# IWRL6432 register map
File version: 1.0
CPU: CM4 1.0, other endian, MPU, FPU, 3 interrupt priority bits
Registers are 32-bit, read-write, reset 0x0 unless marked. A register's access mark holds for its fields unless they carry their own. Offsets are from the block's base; [hi:lo] are bit positions.

## TOP_GIO
Base 0x5AF7FC00
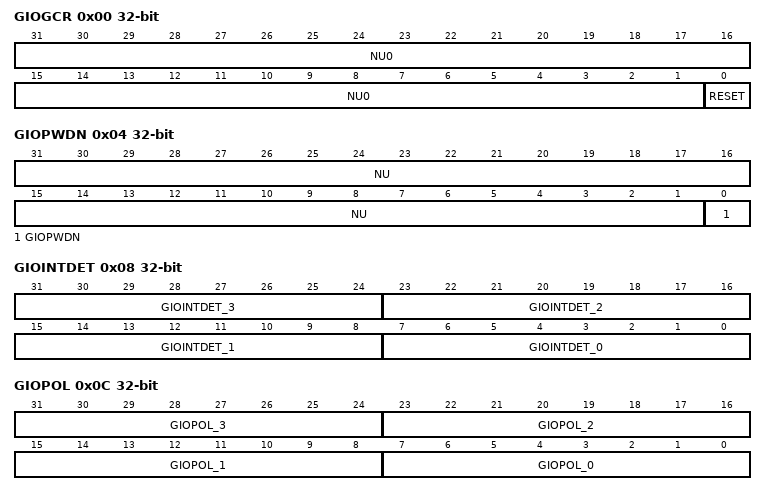
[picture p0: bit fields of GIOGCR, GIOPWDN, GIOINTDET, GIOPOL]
0x00 GIOGCR — GIO reset
  [31:1] NU0 — [31:1] Reserved
  [0] RESET — [0:0] GIO reset
0x04 GIOPWDN — GIO power down mode register
  [31:1] NU — [31:1] Reserved
  [0] GIOPWDN — [0:0] Writing to the GIOPWDN bit is only allowed in privilege mode. Reading of the GIOPWDN bit is allowed in all modes. Privilege mode (write): 0 = Normal operation; clocks enabled to GIO module 1 = Power-down mode User mode (write): Writes have no effect in user mode. User or privilege mode (read): 0 = Normal operation; clocks enabled to GIO module 1 = Power-down mode
0x08 GIOINTDET — Interrupt detection select for pins [0:1] GIO[7:0].
  [31:24] GIOINTDET_3 — [31:24] Interrupt detection select for pins GIOD[7:0].
  [23:16] GIOINTDET_2 — [23:16] Interrupt detection select for pins GIOC[7:0].
  [15:8] GIOINTDET_1 — [15:8] Interrupt detection select for pins GIOB[7:0].
  [7:0] GIOINTDET_0 — [7:0] Interrupt detection select for pins GIOA[7:0].
0x0C GIOPOL — Interrupt polarity select for pins [0:1] GIO[7:0].
  [31:24] GIOPOL_3 — [31:24] Interrupt polarity select for pins GIOD[7:0]
  [23:16] GIOPOL_2 — [23:16] Interrupt polarity select for pins GIOC[7:0]
  [15:8] GIOPOL_1 — [15:8] Interrupt polarity select for pins GIOB[7:0]
  [7:0] GIOPOL_0 — [7:0] Interrupt polarity select for pins GIOA[7:0]
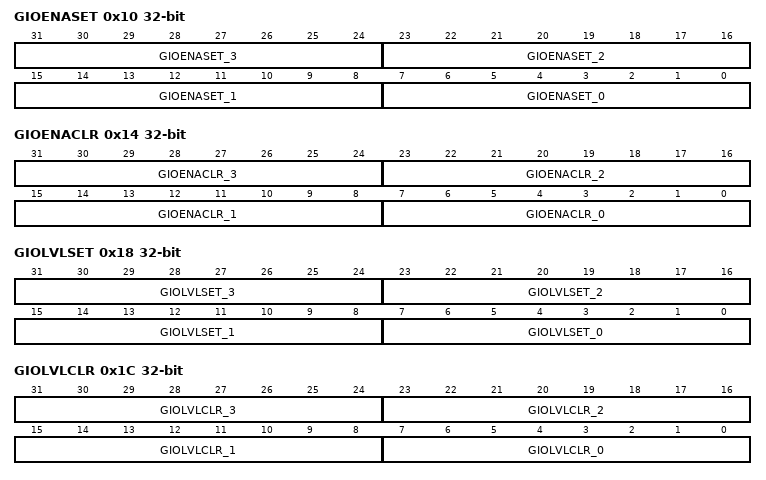
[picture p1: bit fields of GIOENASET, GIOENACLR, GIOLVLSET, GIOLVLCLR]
0x10 GIOENASET — Interrupt enable for pins [0:1] GIO[7:0].
  [31:24] GIOENASET_3 — [31:24] Interrupt enable for pins GIOD [7:0]
  [23:16] GIOENASET_2 — [23:16] Interrupt enable for pins GIOC [7:0]
  [15:8] GIOENASET_1 — [15:8] Interrupt enable for pins GIOB [7:0]
  [7:0] GIOENASET_0 — [7:0] Interrupt enable for pins GIOA [7:0]
0x14 GIOENACLR — Interrupt enable for pins [0:1] GIO[7:0].
  [31:24] GIOENACLR_3 — [31:24] Interrupt enable for pins GIOD [7:0]
  [23:16] GIOENACLR_2 — [23:16] Interrupt enable for pins GIOC [7:0]
  [15:8] GIOENACLR_1 — [15:8] Interrupt enable for pins GIOB [7:0]
  [7:0] GIOENACLR_0 — [7:0] Interrupt enable for pins GIOA [7:0]
0x18 GIOLVLSET — GIO high priority interrupt for pins [0:1] GIO[7:0].
  [31:24] GIOLVLSET_3 — [31:24] GIO high priority interrupt for pins GIOD[7:0]
  [23:16] GIOLVLSET_2 — [23:16] GIO high priority interrupt for pins GIOC[7:0]
  [15:8] GIOLVLSET_1 — [15:8] GIO high priority interrupt for pins GIOB[7:0]
  [7:0] GIOLVLSET_0 — [7:0] GIO high priority interrupt for pins GIOA[7:0]
0x1C GIOLVLCLR — GIO low priority interrupt for pins [0:1] GIO[7:0].
  [31:24] GIOLVLCLR_3 — [31:24] GIO low priority interrupt for pins GIOD[7:0]
  [23:16] GIOLVLCLR_2 — [23:16] GIO low priority interrupt for pins GIOC[7:0]
  [15:8] GIOLVLCLR_1 — [15:8] GIO low priority interrupt for pins GIOB[7:0]
  [7:0] GIOLVLCLR_0 — [7:0] GIO low priority interrupt for pins GIOA[7:0]
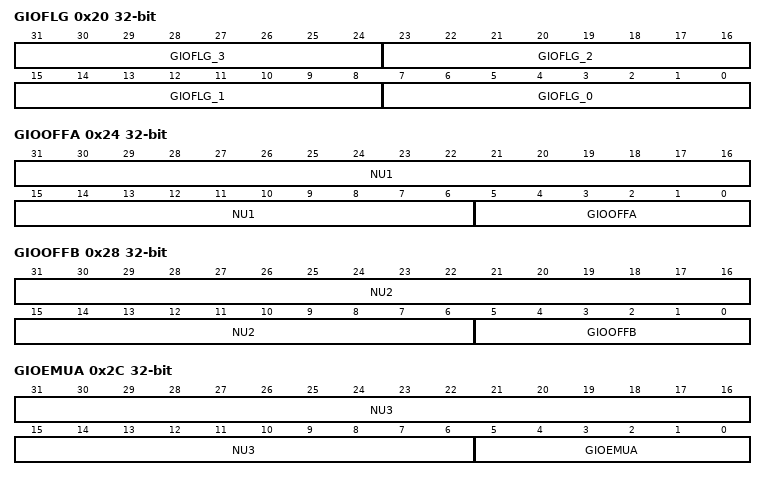
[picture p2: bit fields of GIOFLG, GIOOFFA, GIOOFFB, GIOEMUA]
0x20 GIOFLG — GIO flag for pins [0:1] GIO[7:0].
  [31:24] GIOFLG_3 — [31:24] GIO flag for pins GIOD[7:0]
  [23:16] GIOFLG_2 — [23:16] GIO flag for pins GIOC[7:0]
  [15:8] GIOFLG_1 — [15:8] GIO flag for pins GIOB[7:0]
  [7:0] GIOFLG_0 — [7:0] GIO flag for pins GIOA[7:0]
0x24 GIOOFFA — Index bits for currently pending high-priority interrupt Register A
  [31:6] NU1 — [31:6] Reserved
  [5:0] GIOOFFA — [5:0] Index bits for currently pending high-priority interrupt Register A
0x28 GIOOFFB — Index bits for currently pending high-priority interrupt Register B
  [31:6] NU2 — [31:6] Reserved
  [5:0] GIOOFFB — [5:0] Index bits for currently pending high-priority interrupt Register B
0x2C GIOEMUA — GIO emulation register A
  [31:6] NU3 — [31:6] Reserved
  [5:0] GIOEMUA — [5:0] GIO emulation register A
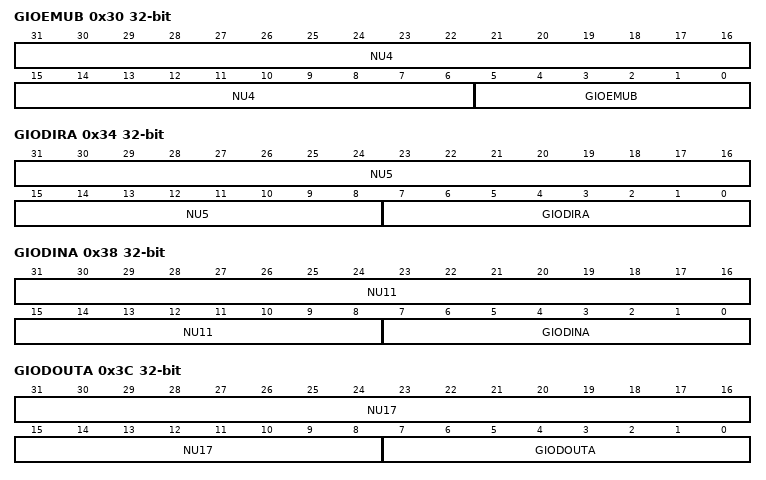
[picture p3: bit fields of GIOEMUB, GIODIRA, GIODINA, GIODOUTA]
0x30 GIOEMUB — GIO emulation register B
  [31:6] NU4 — [31:6] Reserved
  [5:0] GIOEMUB — [5:0] GIO emulation register B
0x34 GIODIRA — GIO data direction of pins in Port A
  [31:8] NU5 — [31:8] Reserved
  [7:0] GIODIRA — [7:0] GIO data direction of pins in Port A
0x38 GIODINA — GIO data input for pins in port A
  [31:8] NU11 — [31:8] Reserved
  [7:0] GIODINA — [7:0] GIO data input for pins in port A
0x3C GIODOUTA — GIO data output for pins in port A
  [31:8] NU17 — [31:8] Reserved
  [7:0] GIODOUTA — [7:0] GIO data output for pins in port A
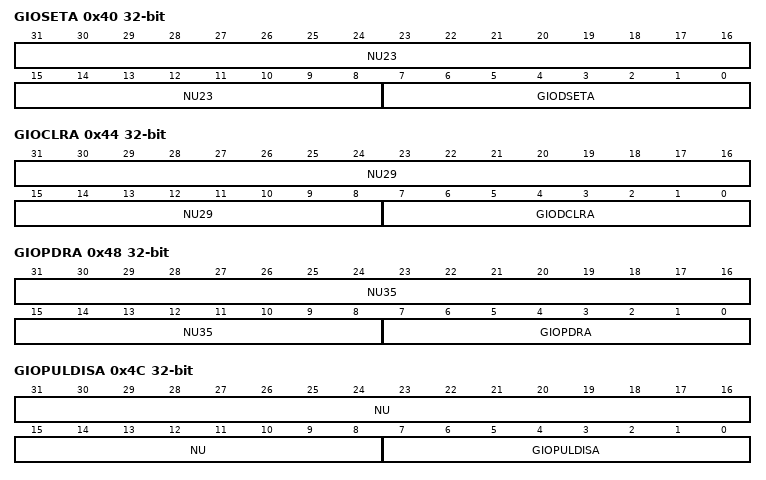
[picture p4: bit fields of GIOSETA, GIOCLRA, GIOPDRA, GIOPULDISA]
0x40 GIOSETA — GIO data set for port A
  [31:8] NU23 — [31:8] Reserved
  [7:0] GIODSETA — [7:0] GIO data set for port A
0x44 GIOCLRA — GIO data clear for port A
  [31:8] NU29 — [31:8] Reserved
  [7:0] GIODCLRA — [7:0] GIO data clear for port A
0x48 GIOPDRA — GIO open drain for port A
  [31:8] NU35 — [31:8] Reserved
  [7:0] GIOPDRA — [7:0] GIO open drain for port A
0x4C GIOPULDISA — GIO pul disable for port A
  [31:8] NU — [31:8] Reserved
  [7:0] GIOPULDISA — [7:0] GIO pull disable for port A
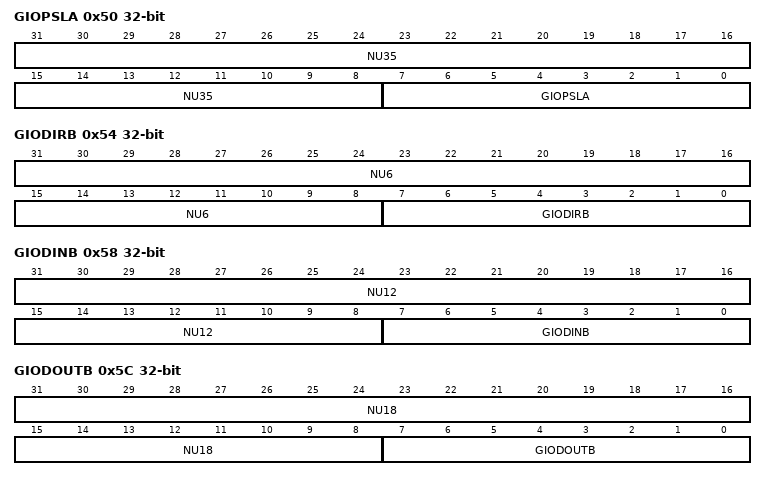
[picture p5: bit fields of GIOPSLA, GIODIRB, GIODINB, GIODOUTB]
0x50 GIOPSLA — GIO pul select for port A
  [31:8] NU35 — [31:8] Reserved
  [7:0] GIOPSLA — [7:0] GIO pull select for port A
0x54 GIODIRB — GIO data direction of pins in Port B
  [31:8] NU6 — [31:8] Reserved
  [7:0] GIODIRB — [7:0] GIO data direction of pins in Port B
0x58 GIODINB — GIO data input for pins in port B
  [31:8] NU12 — [31:8] Reserved
  [7:0] GIODINB — [7:0] GIO data input for pins in port B
0x5C GIODOUTB — GIO data output for pins in port B
  [31:8] NU18 — [31:8] Reserved
  [7:0] GIODOUTB — [7:0] GIO data output for pins in port B
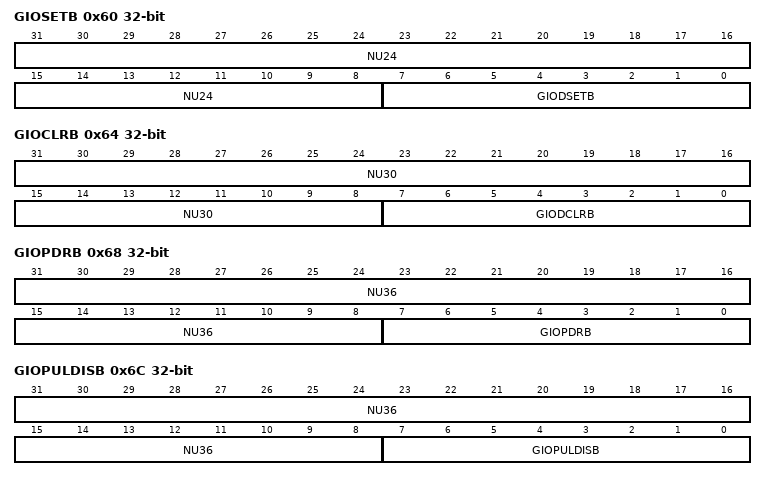
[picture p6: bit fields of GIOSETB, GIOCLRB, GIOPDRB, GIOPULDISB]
0x60 GIOSETB — GIO data set for port B
  [31:8] NU24 — [31:8] Reserved
  [7:0] GIODSETB — [7:0] GIO data set for port B
0x64 GIOCLRB — GIO data clear for port B
  [31:8] NU30 — [31:8] Reserved
  [7:0] GIODCLRB — [7:0] GIO data clear for port B
0x68 GIOPDRB — GIO open drain for port B
  [31:8] NU36 — [31:8] Reserved
  [7:0] GIOPDRB — [7:0] GIO open drain for port B
0x6C GIOPULDISB — GIO pul disable for port B
  [31:8] NU36 — [31:8] Reserved
  [7:0] GIOPULDISB — [7:0] GIO pull disable for port B
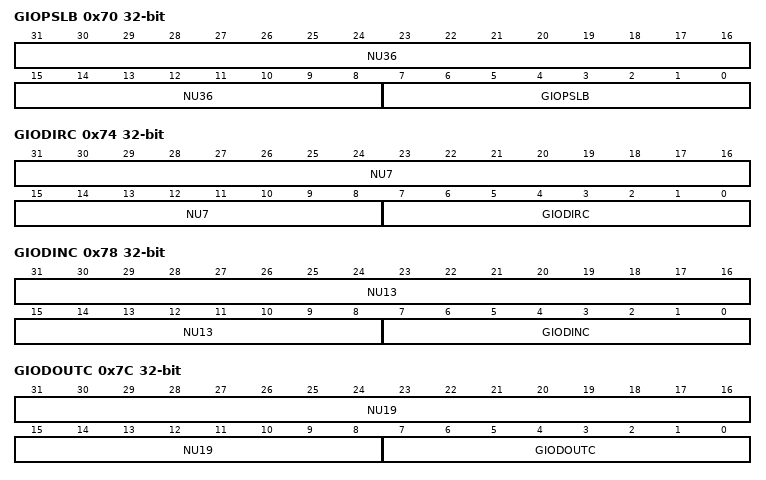
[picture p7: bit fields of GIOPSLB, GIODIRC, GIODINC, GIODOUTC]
0x70 GIOPSLB — GIO pul select for port B
  [31:8] NU36 — [31:8] Reserved
  [7:0] GIOPSLB — [7:0] GIO pull select for port B
0x74 GIODIRC — GIO data direction of pins in Port C
  [31:8] NU7 — [31:8] Reserved
  [7:0] GIODIRC — [7:0] GIO data direction of pins in Port C
0x78 GIODINC — GIO data input for pins in port C
  [31:8] NU13 — [31:8] Reserved
  [7:0] GIODINC — [7:0] GIO data input for pins in port C
0x7C GIODOUTC — GIO data output for pins in port C
  [31:8] NU19 — [31:8] Reserved
  [7:0] GIODOUTC — [7:0] GIO data output for pins in port C
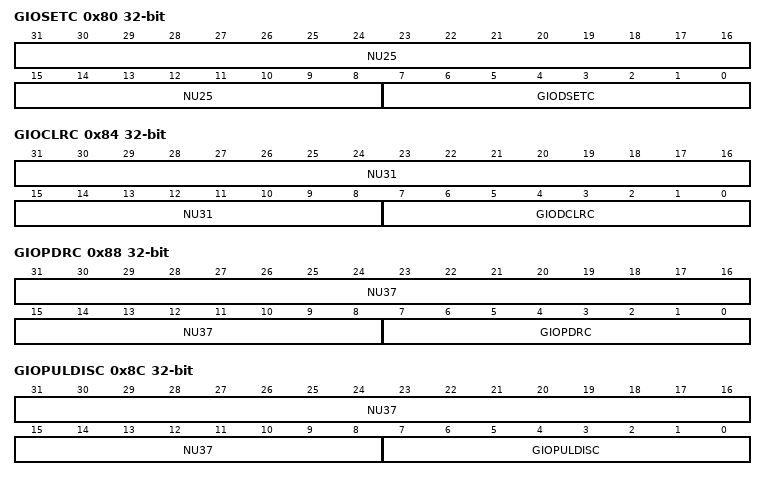
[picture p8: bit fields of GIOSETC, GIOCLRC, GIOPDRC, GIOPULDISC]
0x80 GIOSETC — GIO data set for port C
  [31:8] NU25 — [31:8] Reserved
  [7:0] GIODSETC — [7:0] GIO data set for port C
0x84 GIOCLRC — GIO data clear for port C
  [31:8] NU31 — [31:8] Reserved
  [7:0] GIODCLRC — [7:0] GIO data clear for port C
0x88 GIOPDRC — GIO open drain for port C
  [31:8] NU37 — [31:8] Reserved
  [7:0] GIOPDRC — [7:0] GIO open drain for port C
0x8C GIOPULDISC — GIO pul disable for port C
  [31:8] NU37 — [31:8] Reserved
  [7:0] GIOPULDISC — [7:0] GIO pull disable for port C
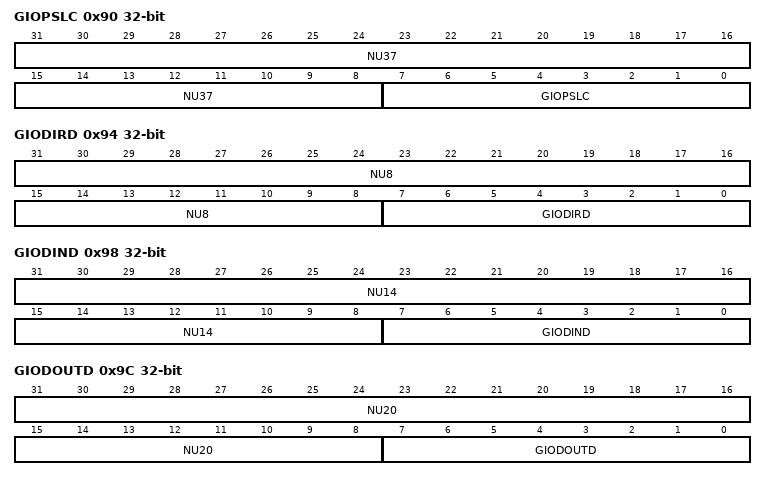
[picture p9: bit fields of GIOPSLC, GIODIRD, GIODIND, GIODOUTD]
0x90 GIOPSLC — GIO pul select for port C
  [31:8] NU37 — [31:8] Reserved
  [7:0] GIOPSLC — [7:0] GIO pull select for port C
0x94 GIODIRD — GIO data direction of pins in Port D
  [31:8] NU8 — [31:8] Reserved
  [7:0] GIODIRD — [7:0] GIO data direction of pins in Port D
0x98 GIODIND — GIO data input for pins in port D
  [31:8] NU14 — [31:8] Reserved
  [7:0] GIODIND — [7:0] GIO data input for pins in port D
0x9C GIODOUTD — GIO data output for pins in port D
  [31:8] NU20 — [31:8] Reserved
  [7:0] GIODOUTD — [7:0] GIO data output for pins in port D
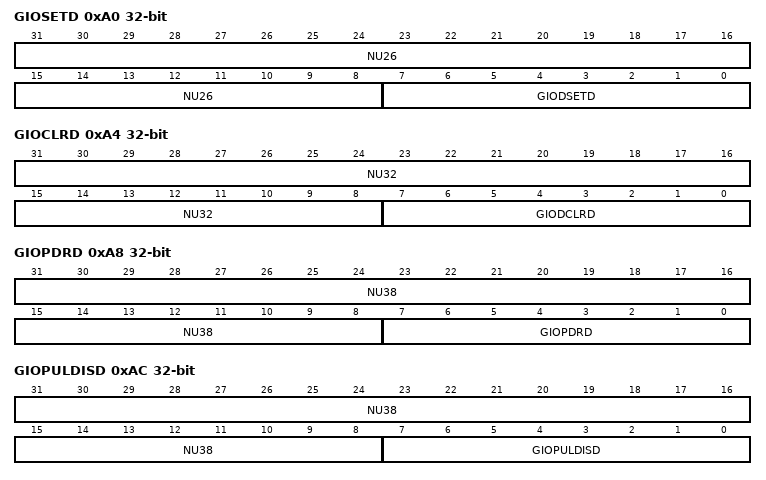
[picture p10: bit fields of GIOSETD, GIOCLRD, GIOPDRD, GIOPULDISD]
0xA0 GIOSETD — GIO data set for port D
  [31:8] NU26 — [31:8] Reserved
  [7:0] GIODSETD — [7:0] GIO data set for port D
0xA4 GIOCLRD — GIO data clear for port D
  [31:8] NU32 — [31:8] Reserved
  [7:0] GIODCLRD — [7:0] GIO data clear for port D
0xA8 GIOPDRD — GIO open drain for port D
  [31:8] NU38 — [31:8] Reserved
  [7:0] GIOPDRD — [7:0] GIO open drain for port D
0xAC GIOPULDISD — GIO pul disable for port D
  [31:8] NU38 — [31:8] Reserved
  [7:0] GIOPULDISD — [7:0] GIO pull disable for port D
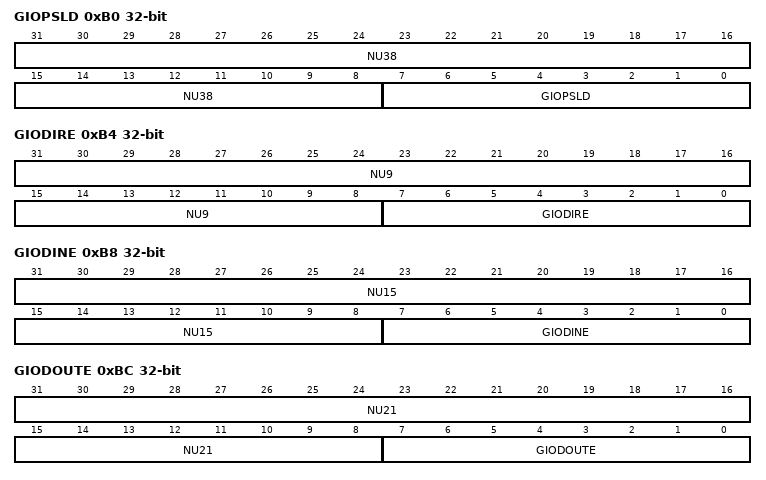
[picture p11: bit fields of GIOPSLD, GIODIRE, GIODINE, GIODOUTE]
0xB0 GIOPSLD — GIO pul select for port D
  [31:8] NU38 — [31:8] Reserved
  [7:0] GIOPSLD — [7:0] GIO pull select for port D
0xB4 GIODIRE — GIO data direction of pins in Port E
  [31:8] NU9 — [31:8] Reserved
  [7:0] GIODIRE — [7:0] GIO data direction of pins in Port E
0xB8 GIODINE — GIO data input for pins in port E
  [31:8] NU15 — [31:8] Reserved
  [7:0] GIODINE — [7:0] GIO data input for pins in port E
0xBC GIODOUTE — GIO data output for pins in port E
  [31:8] NU21 — [31:8] Reserved
  [7:0] GIODOUTE — [7:0] GIO data output for pins in port E
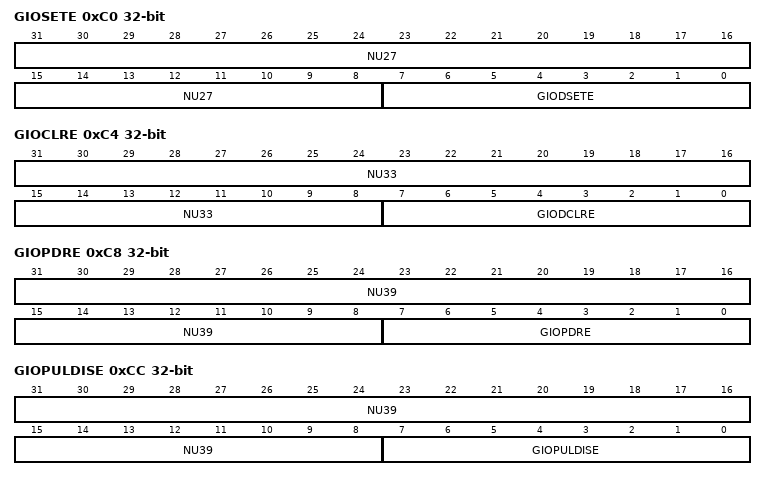
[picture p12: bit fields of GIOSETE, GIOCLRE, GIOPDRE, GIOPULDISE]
0xC0 GIOSETE — GIO data set for port E
  [31:8] NU27 — [31:8] Reserved
  [7:0] GIODSETE — [7:0] GIO data set for port E
0xC4 GIOCLRE — GIO data clear for port E
  [31:8] NU33 — [31:8] Reserved
  [7:0] GIODCLRE — [7:0] GIO data clear for port E
0xC8 GIOPDRE — GIO open drain for port E
  [31:8] NU39 — [31:8] Reserved
  [7:0] GIOPDRE — [7:0] GIO open drain for port E
0xCC GIOPULDISE — GIO pul disable for port E
  [31:8] NU39 — [31:8] Reserved
  [7:0] GIOPULDISE — [7:0] GIO pull disable for port E
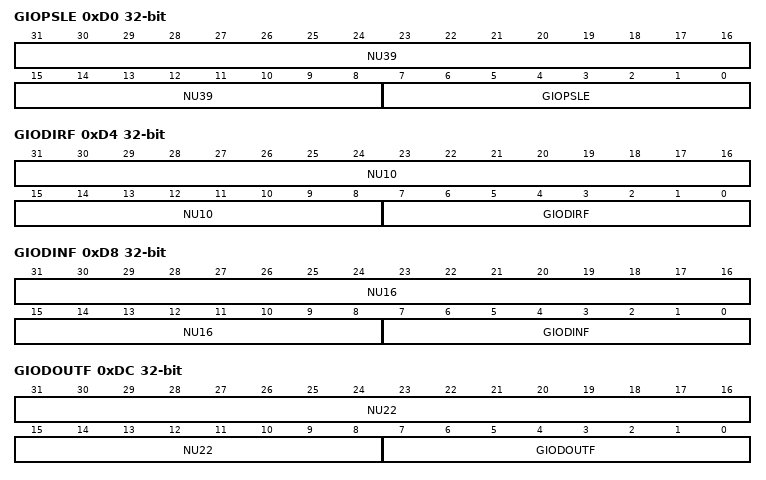
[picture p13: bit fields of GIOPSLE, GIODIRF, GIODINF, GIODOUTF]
0xD0 GIOPSLE — GIO pul select for port E
  [31:8] NU39 — [31:8] Reserved
  [7:0] GIOPSLE — [7:0] GIO pull select for port E
0xD4 GIODIRF — GIO data direction of pins in Port F
  [31:8] NU10 — [31:8] Reserved
  [7:0] GIODIRF — [7:0] GIO data direction of pins in Port F
0xD8 GIODINF — GIO data input for pins in Port F
  [31:8] NU16 — [31:8] Reserved
  [7:0] GIODINF — [7:0] GIO data input for pins in port F
0xDC GIODOUTF — GIO data output for pins in Port F
  [31:8] NU22 — [31:8] Reserved
  [7:0] GIODOUTF — [7:0] GIO data output for pins in port F
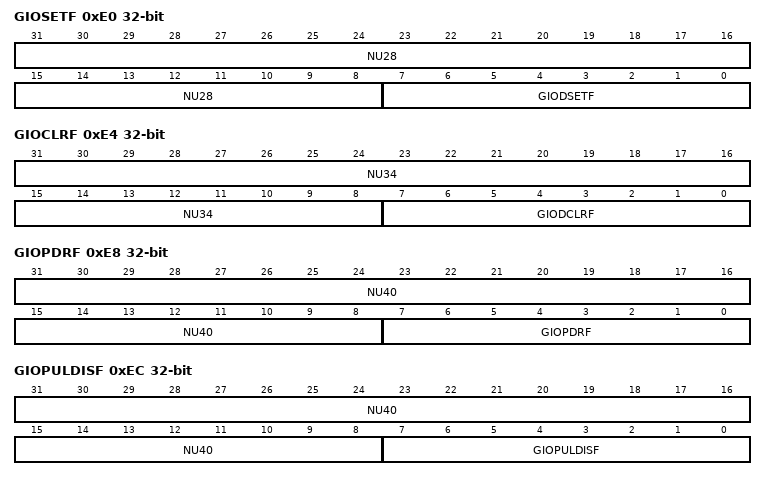
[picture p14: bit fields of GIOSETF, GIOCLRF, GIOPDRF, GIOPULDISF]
0xE0 GIOSETF — GIO data set for Port F
  [31:8] NU28 — [31:8] Reserved
  [7:0] GIODSETF — [7:0] GIO data set for port F
0xE4 GIOCLRF — GIO data clear for Port F
  [31:8] NU34 — [31:8] Reserved
  [7:0] GIODCLRF — [7:0] GIO data clear for port F
0xE8 GIOPDRF — GIO open drain for Port F
  [31:8] NU40 — [31:8] Reserved
  [7:0] GIOPDRF — [7:0] GIO open drain for port F
0xEC GIOPULDISF — GIO pul disable for port F
  [31:8] NU40 — [31:8] Reserved
  [7:0] GIOPULDISF — [7:0] GIO pull disable for port F
0xF0 GIOPSLF — GIO pul select for port F
  [31:8] NU40 — [31:8] Reserved
  [7:0] GIOPSLF — [7:0] GIO pull select for port F
0xF4 GIODIRG — GIO data direction of pins in Port G
  [31:8] NU9 — [31:8] Reserved
  [7:0] GIODIRG — [7:0] GIO data direction of pins in Port G
0xF8 GIODING — GIO data input for pins in port G
  [31:8] NU15 — [31:8] Reserved
  [7:0] GIODING — [7:0] GIO data input for pins in port G
0xFC GIODOUTG — GIO data output for pins in port G
  [31:8] NU21 — [31:8] Reserved
  [7:0] GIODOUTG — [7:0] GIO data output for pins in port G
0x100 GIOSETG — GIO data set for port G
  [31:8] NU27 — [31:8] Reserved
  [7:0] GIODSETG — [7:0] GIO data set for port G
0x104 GIOCLRG — GIO data clear for port G
  [31:8] NU33 — [31:8] Reserved
  [7:0] GIODCLRG — [7:0] GIO data clear for port G
0x108 GIOPDRG — GIO open drain for port G
  [31:8] NU39 — [31:8] Reserved
  [7:0] GIOPDRG — [7:0] GIO open drain for port G
0x10C GIOPULDISG — GIO pul disable for port G
  [31:8] NU39 — [31:8] Reserved
  [7:0] GIOPULDISG — [7:0] GIO pull disable for port G
0x110 GIOPSLG — GIO pul select for port G
  [31:8] NU39 — [31:8] Reserved
  [7:0] GIOPSLG — [7:0] GIO pull select for port G
0x114 GIODIRH — GIO data direction of pins in Port H
  [31:8] NU10 — [31:8] Reserved
  [7:0] GIODIRH — [7:0] GIO data direction of pins in Port H
0x118 GIODINH — GIO data input for pins in Port H
  [31:8] NU16 — [31:8] Reserved
  [7:0] GIODINH — [7:0] GIO data input for pins in port H
0x11C GIODOUTH — GIO data output for pins in Port H
  [31:8] NU22 — [31:8] Reserved
  [7:0] GIODOUTH — [7:0] GIO data output for pins in port H
0x120 GIOSETH — GIO data set for Port H
  [31:8] NU28 — [31:8] Reserved
  [7:0] GIODSETH — [7:0] GIO data set for port H
0x124 GIOCLRH — GIO data clear for Port H
  [31:8] NU34 — [31:8] Reserved
  [7:0] GIODCLRH — [7:0] GIO data clear for port H
0x128 GIOPDRH — GIO open drain for Port H
  [31:8] NU40 — [31:8] Reserved
  [7:0] GIOPDRH — [7:0] GIO open drain for port H
0x12C GIOPULDISH — GIO pul disable for port H
  [31:8] NU40 — [31:8] Reserved
  [7:0] GIOPULDISH — [7:0] GIO pull disable for port H
0x130 GIOPSLH — GIO pul select for port H
  [31:8] NU40 — [31:8] Reserved
  [7:0] GIOPSLH — [7:0] GIO pull select for port H
0x134 GIOSRCA — GIO slew rate select for port A
  [31:8] NU35 — [31:8] Reserved
  [7:0] GIOSRCA — [7:0] GIO slew rate control for port A
0x138 GIOSRCB — GIO slew rate select for port B
  [31:8] NU36 — [31:8] Reserved
  [7:0] GIOSRCB — [7:0] GIO slew rate control for port B
0x13C GIOSRCC — GIO slew rate select for port C
  [31:8] NU37 — [31:8] Reserved
  [7:0] GIOSRCC — [7:0] GIO slew rate control for port C
0x140 GIOSRCD — GIO slew rate select for port D
  [31:8] NU38 — [31:8] Reserved
  [7:0] GIOSRCD — [7:0] GIO slew rate control for port D
0x144 GIOSRCE — GIO slew rate select for port E
  [31:8] NU39 — [31:8] Reserved
  [7:0] GIOSRCE — [7:0] GIO slew rate control for port E
0x148 GIOSRCF — GIO slew rate select for port F
  [31:8] NU40 — [31:8] Reserved
  [7:0] GIOSRCF — [7:0] GIO slew rate control for port F
0x14C GIOSRCG — GIO slew rate select for port G
  [31:8] NU39 — [31:8] Reserved
  [7:0] GIOSRCG — [7:0] GIO slew rate control for port G
0x150 GIOSRCH — GIO slew rate select for port H
  [31:8] NU40 — [31:8] Reserved
  [7:0] GIOSRCH — [7:0] GIO slew rate control for port H
